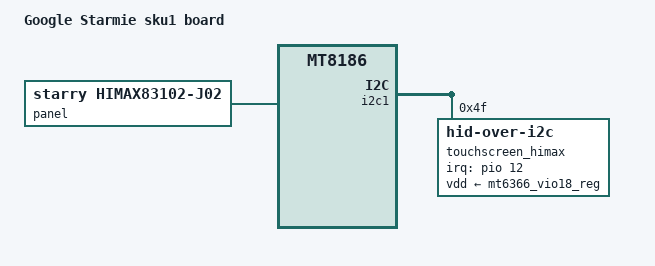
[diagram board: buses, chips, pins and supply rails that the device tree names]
// SPDX-License-Identifier: (GPL-2.0 OR MIT)
/*
 * Copyright 2023 Google LLC
 */

/dts-v1/;
#include "mt8186-corsola-starmie.dtsi"

/ {
	model = "Google Starmie sku1 board";
	compatible = "google,starmie-sku1", "google,starmie-sku4",
		     "google,starmie", "mediatek,mt8186";
};

&panel {
	compatible = "starry,himax83102-j02", "himax,hx83102";
};

&i2c1 {
	touchscreen_himax: touchscreen@4f {
		compatible = "hid-over-i2c";
		reg = <0x4f>;
		interrupts-extended = <&pio 12 IRQ_TYPE_LEVEL_LOW>;
		pinctrl-names = "default";
		pinctrl-0 = <&touchscreen_pins>;
		vdd-supply = <&mt6366_vio18_reg>;
		panel = <&panel>;
		post-power-on-delay-ms = <450>;
		hid-descr-addr = <0x0001>;
	};
};
